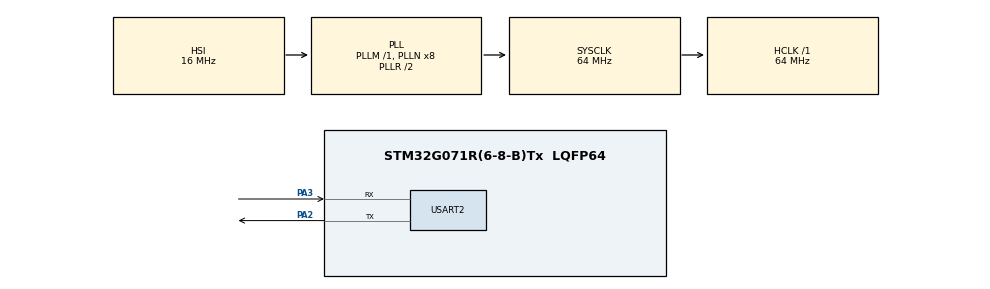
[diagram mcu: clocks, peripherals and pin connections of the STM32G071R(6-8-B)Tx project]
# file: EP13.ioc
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CRC.DefaultInitValueUse=DEFAULT_INIT_VALUE_ENABLE
CRC.DefaultPolynomialUse=DEFAULT_POLYNOMIAL_ENABLE
CRC.InputDataFormat=CRC_INPUTDATA_FORMAT_WORDS
Mcu.Family=STM32G0
Mcu.Name=STM32G071R(6-8-B)Tx
Mcu.Package=LQFP64
PA2.Mode=Asynchronous
PA2.Signal=USART2_TX
PA3.Mode=Asynchronous
PA3.Signal=USART2_RX
ProjectManager.HeapSize=0x200
ProjectManager.StackSize=0x400
ProjectManager.TargetToolchain=STM32CubeIDE
RCC.ADCFreq_Value=64000000
RCC.AHBFreq_Value=64000000
RCC.CortexFreq_Value=64000000
RCC.EXTERNAL_CLOCK_VALUE=48000
RCC.HCLKFreq_Value=64000000
RCC.HSE_VALUE=8000000
RCC.HSI_VALUE=16000000
RCC.LSE_VALUE=32768
RCC.SYSCLKFreq_VALUE=64000000
RCC.SYSCLKSource=RCC_SYSCLKSOURCE_PLLCLK
RCC.VCOOutputFreq_Value=128000000
USART2.VirtualMode-Asynchronous=VM_ASYNC
VP_CRC_VS_CRC.Mode=CRC_Activate
board=custom

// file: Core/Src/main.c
/* USER CODE BEGIN Header */
/**
  ******************************************************************************
  * @file           : main.c
  * @brief          : Main program body
  ******************************************************************************
  * @attention
  *
  * Copyright (c) 2025 STMicroelectronics.
  * All rights reserved.
  *
  * This software is licensed under terms that can be found in the LICENSE file
  * in the root directory of this software component.
  * If no LICENSE file comes with this software, it is provided AS-IS.
  *
  ******************************************************************************
  */
/* USER CODE END Header */
#include "main.h"
#include "crc.h"
#include "usart.h"
#include "gpio.h"

/* USER CODE BEGIN Includes */
#include "stdio.h"
/* USER CODE END Includes */

/* USER CODE BEGIN PV */
uint32_t data[5] = {0x12345678, 0x87654321, 0xAABBCCDD, 0x11223344, 0xDEADBEEF};
__IO uint32_t u32CRCValueHw = 0;
__IO uint32_t u32CRCValueSoft= 0xFFFFFFFF;
/* USER CODE END PV */

void SystemClock_Config(void);
/* USER CODE BEGIN PFP */
uint32_t Crc32(uint32_t Crc, uint32_t Data);
/* USER CODE END PFP */

/* USER CODE BEGIN 0 */
int __io_putchar(int ch)
{
	HAL_UART_Transmit(&huart2,(uint8_t *) &ch, 1, 100);
	return ch;
}
/* USER CODE END 0 */

int main(void)
{

  /* MCU Configuration--------------------------------------------------------*/

  /* Reset of all peripherals, Initializes the Flash interface and the Systick. */
  HAL_Init();

  /* Configure the system clock */
  SystemClock_Config();

  /* Initialize all configured peripherals */
  MX_GPIO_Init();
  MX_CRC_Init();
  MX_USART2_UART_Init();
  /* USER CODE BEGIN 2 */
  printf("\n\r================================ CRC TEST ================================\n\r");
  u32CRCValueHw = HAL_CRC_Calculate(&hcrc, data, 5);
  for(uint8_t i = 0; i <5; i++)
  {
	  u32CRCValueSoft = Crc32(u32CRCValueSoft, data[i]);
  }
	printf("\tChecksum generated by STM32 hardware CRC Unit = 0x%08X\n\r", (unsigned int)u32CRCValueHw);
	printf("\tChecksum generated by STM32 software CRC      = 0x%08X\n\r", (unsigned int)u32CRCValueSoft);
  /* USER CODE END 2 */

  /* Infinite loop */
  while (1)
  {

  }
}

void SystemClock_Config(void)
{
  RCC_OscInitTypeDef RCC_OscInitStruct = {0};
  RCC_ClkInitTypeDef RCC_ClkInitStruct = {0};

  /** Configure the main internal regulator output voltage
  */
  HAL_PWREx_ControlVoltageScaling(PWR_REGULATOR_VOLTAGE_SCALE1);

  /** Initializes the RCC Oscillators according to the specified parameters
  * in the RCC_OscInitTypeDef structure.
  */
  RCC_OscInitStruct.OscillatorType = RCC_OSCILLATORTYPE_HSI;
  RCC_OscInitStruct.HSIState = RCC_HSI_ON;
  RCC_OscInitStruct.HSIDiv = RCC_HSI_DIV1;
  RCC_OscInitStruct.HSICalibrationValue = RCC_HSICALIBRATION_DEFAULT;
  RCC_OscInitStruct.PLL.PLLState = RCC_PLL_ON;
  RCC_OscInitStruct.PLL.PLLSource = RCC_PLLSOURCE_HSI;
  RCC_OscInitStruct.PLL.PLLM = RCC_PLLM_DIV1;
  RCC_OscInitStruct.PLL.PLLN = 8;
  RCC_OscInitStruct.PLL.PLLP = RCC_PLLP_DIV2;
  RCC_OscInitStruct.PLL.PLLQ = RCC_PLLQ_DIV2;
  RCC_OscInitStruct.PLL.PLLR = RCC_PLLR_DIV2;
  if (HAL_RCC_OscConfig(&RCC_OscInitStruct) != HAL_OK)
  {
    Error_Handler();
  }

  /** Initializes the CPU, AHB and APB buses clocks
  */
  RCC_ClkInitStruct.ClockType = RCC_CLOCKTYPE_HCLK|RCC_CLOCKTYPE_SYSCLK
                              |RCC_CLOCKTYPE_PCLK1;
  RCC_ClkInitStruct.SYSCLKSource = RCC_SYSCLKSOURCE_PLLCLK;
  RCC_ClkInitStruct.AHBCLKDivider = RCC_SYSCLK_DIV1;
  RCC_ClkInitStruct.APB1CLKDivider = RCC_HCLK_DIV1;

  if (HAL_RCC_ClockConfig(&RCC_ClkInitStruct, FLASH_LATENCY_2) != HAL_OK)
  {
    Error_Handler();
  }
}

/* USER CODE BEGIN 4 */
uint32_t Crc32(uint32_t Crc, uint32_t Data)
{
	uint8_t index;

	Crc = Crc ^ Data;
	for(index=0; index<32; index++)
	{
		if (Crc & 0x80000000)
			Crc = (Crc << 1) ^ 0x04C11DB7; // Polynomial used in STM32
		else
			Crc = (Crc << 1);
	}
	return(Crc);
}
/* USER CODE END 4 */

void Error_Handler(void)
{
  __disable_irq();
  while (1)
  {
  }
}
